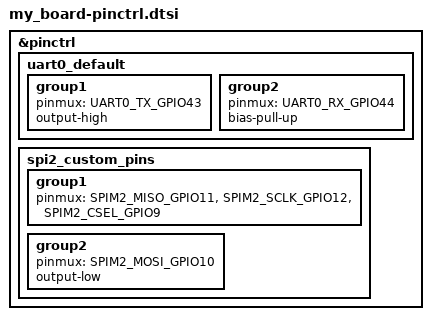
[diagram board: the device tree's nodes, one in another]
#include <zephyr/dt-bindings/pinctrl/esp-pinctrl-common.h>
#include <dt-bindings/pinctrl/esp32s3-pinctrl.h>
#include <zephyr/dt-bindings/pinctrl/esp32s3-gpio-sigmap.h>

&pinctrl {
	uart0_default: uart0_default {
		group1 {
			pinmux = <UART0_TX_GPIO43>;
			output-high;
		};
		group2 {
			pinmux = <UART0_RX_GPIO44>;
			bias-pull-up;
		};
	};

	spi2_custom_pins: spi2_custom_pins {
        group1 {
			pinmux = <SPIM2_MISO_GPIO11>,
				     <SPIM2_SCLK_GPIO12>,
				     <SPIM2_CSEL_GPIO9>;
		};
		group2 {
			pinmux = <SPIM2_MOSI_GPIO10>;
			output-low;
		};
    };
};
